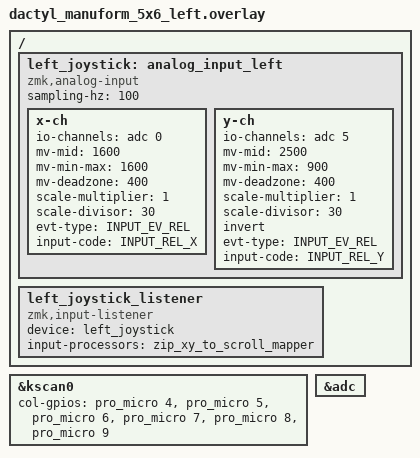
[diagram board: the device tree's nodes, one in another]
#include "dactyl_manuform_5x6.dtsi" // Notice that the main dtsi files are included in the overlay.
#include <zephyr/dt-bindings/input/input-event-codes.h>
#include <input/processors.dtsi>

&kscan0 {
    col-gpios
        = <&pro_micro 4 GPIO_ACTIVE_HIGH>
        , <&pro_micro 5 GPIO_ACTIVE_HIGH>
        , <&pro_micro 6 GPIO_ACTIVE_HIGH>
        , <&pro_micro 7 GPIO_ACTIVE_HIGH>
        , <&pro_micro 8 GPIO_ACTIVE_HIGH>
        , <&pro_micro 9 GPIO_ACTIVE_HIGH>
        ;
};

&adc {
    status = "okay";
};

/ {
    // Left joystick for scroll wheel functionality
    left_joystick: analog_input_left {
        compatible = "zmk,analog-input";
        sampling-hz = <100>;
        x-ch {
            io-channels = <&adc 0>; // X-axis on pin P0.02/AIN0
            mv-mid = <1600>;
            mv-min-max = <1600>;
            mv-deadzone = <400>;
            scale-multiplier = <1>;
            scale-divisor = <30>;
            evt-type = <INPUT_EV_REL>;
            input-code = <INPUT_REL_X>;
        };
        y-ch {
            io-channels = <&adc 5>; // Y-axis on pin P0.29/AIN5
            mv-mid = <2500>;
            mv-min-max = <900>;
            mv-deadzone = <400>;
            scale-multiplier = <1>;
            scale-divisor = <30>;
            invert;
            evt-type = <INPUT_EV_REL>;
            input-code = <INPUT_REL_Y>;
        };
    };

    // Input listener for left joystick scroll functionality
    left_joystick_listener {
        compatible = "zmk,input-listener";
        device = <&left_joystick>;
        input-processors = <&zip_xy_to_scroll_mapper>;
    };
};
